# ADC12_2 register map
Vendor: Texas Instruments
Peripheral module from a debugger description file (folder msp430).
Registers are 16-bit, read-write, reset 0x0 unless marked. A register's access mark holds for its fields unless they carry their own. Offsets are as the file gives them; lines under a group give offsets from that group; [hi:lo] are bit positions; {n}, {i} and the like mark numbered series; 'fields as' and 'values as' point back to an identical list; <NAME> marks a mode.

## ADC12
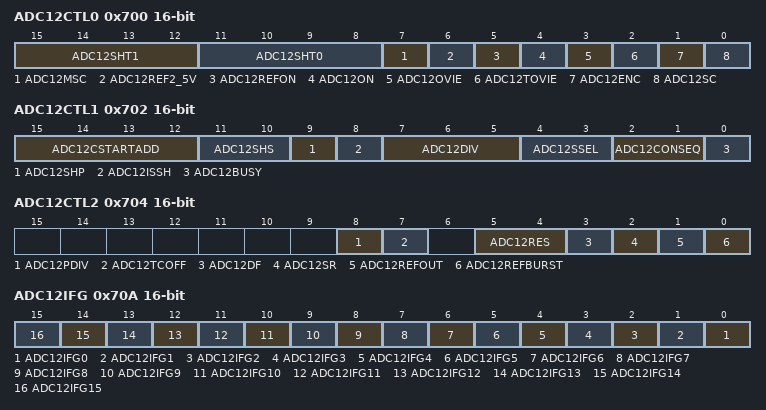
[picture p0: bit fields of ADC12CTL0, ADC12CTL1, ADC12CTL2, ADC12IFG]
0x700 ADC12CTL0 — ADC12+ Control 0
  [15:12] ADC12SHT1 — ADC12 Sample Hold 1 Select Bit: 0
    {v}=ADC12 Sample Hold 1 Select Bit: {v} (v=0..15)
  [11:8] ADC12SHT0 — ADC12 Sample Hold 0 Select Bit: 0
    {v}=ADC12 Sample Hold 0 Select Bit: {v} (v=0..15)
  [7] ADC12MSC — ADC12 Multiple SampleConversion
  [6] ADC12REF2_5V — ADC12 Ref 0:1.5V / 1:2.5V
  [5] ADC12REFON — ADC12 Reference on
  [4] ADC12ON — ADC12 On/enable
  [3] ADC12OVIE — ADC12 Overflow interrupt enable
  [2] ADC12TOVIE — ADC12 Timer Overflow interrupt enable
  [1] ADC12ENC — ADC12 Enable Conversion
  [0] ADC12SC — ADC12 Start Conversion
0x702 ADC12CTL1 — ADC12+ Control 1
  [15:12] ADC12CSTARTADD — ADC12 Conversion Start Address Bit: 0
    {v}=ADC12 Conversion Start Address: {v} (v=0..15)
  [11:10] ADC12SHS — ADC12 Sample/Hold Source Bit: 0
    {v}=ADC12 Sample/Hold Source: {v} (v=0..3)
  [9] ADC12SHP — ADC12 Sample/Hold Pulse Mode
  [8] ADC12ISSH — ADC12 Invert Sample Hold Signal
  [7:5] ADC12DIV — ADC12 Clock Divider Select Bit: 0
    {v}=ADC12 Clock Divider Select: {v} (v=0..7)
  [4:3] ADC12SSEL — ADC12 Clock Source Select Bit: 0
    {v}=ADC12 Clock Source Select: {v} (v=0..3)
  [2:1] ADC12CONSEQ — ADC12 Conversion Sequence Select Bit: 0
    {v}=ADC12 Conversion Sequence Select: {v} (v=0..3)
  [0] ADC12BUSY
0x704 ADC12CTL2 — ADC12+ Control 2
  [8] ADC12PDIV — ADC12+ predivider 0:/1 1:/4
  [7] ADC12TCOFF — ADC12+ Temperature Sensor Off
  [5:4] ADC12RES — ADC12+ Resolution Bit: 0
    0=ADC12+ Resolution : 8 Bit; 1=ADC12+ Resolution : 10 Bit; 2=ADC12+ Resolution : 12 Bit; 3=ADC12+ Resolution : reserved
  [3] ADC12DF — ADC12+ Data Format
  [2] ADC12SR — ADC12+ Sampling Rate
  [1] ADC12REFOUT — ADC12+ Reference Out
  [0] ADC12REFBURST — ADC12+ Reference Burst
0x70A ADC12IFG — ADC12+ Interrupt Flag
  [n] ADC12IFG{n} (n=0..15) — ADC12 Memory {n} Interrupt Flag
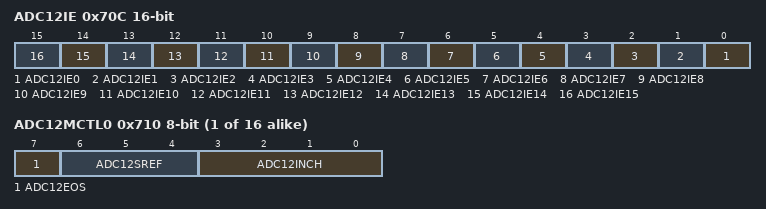
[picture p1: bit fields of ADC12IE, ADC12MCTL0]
0x70C ADC12IE — ADC12+ Interrupt Enable
  [n] ADC12IE{n} (n=0..15) — ADC12 Memory {n} Interrupt Enable
0x70E ADC12IV access not given reset not defined — ADC12+ Interrupt Vector Word
{0x710+i} ADC12MCTL{i} 8-bit (i=0..15) — ADC12 Memory Control {i}
  [7] ADC12EOS — ADC12 End of Sequence
  [6:4] ADC12SREF — ADC12 Select Reference Bit 0
    {v}=ADC12 Select Reference {v} (v=0..7)
  [3:0] ADC12INCH — ADC12 Input Channel Select Bit 0
    {v}=ADC12 Input Channel {v} (v=0..15)
{0x720+2i} ADC12MEM{i} access not given reset not defined (i=0..15) — ADC12 Conversion Memory {i}
